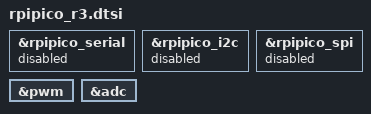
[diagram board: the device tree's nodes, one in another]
/*
 * SPDX-FileCopyrightText: Copyright (c) 2023-2026 TiaC Systems
 * SPDX-License-Identifier: Apache-2.0
 */

&rpipico_serial {
	status = "disabled";
};

&rpipico_i2c {
	status = "disabled";
};

&rpipico_spi {
	status = "disabled";
};

/* link to pwm node from board for RP2040 SoC */
pico_pwm: &pwm {};

/* link to adc node from board for RP2040 SoC */
pico_adc: &adc {};
